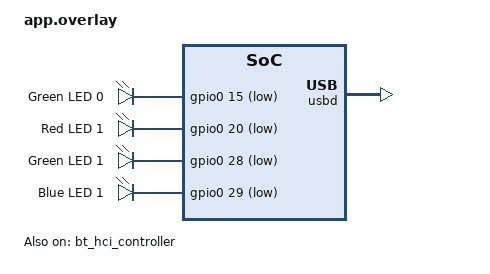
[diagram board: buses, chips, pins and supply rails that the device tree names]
/ {
	chosen {
		zephyr,bt-hci = &bt_hci_controller;
	};

	/* Configure DTS nodes used for USB next HID support. */
	hid_dev_0: hid_dev_0 {
		compatible = "zephyr,hid-device";
		interface-name = "HID0";
		protocol-code = "none";
		in-polling-period-us = <1000>;
		in-report-size = <64>;
	};
	hid_dev_1: hid_dev_1 {
		compatible = "zephyr,hid-device";
		interface-name = "HID1";
		protocol-code = "none";
		in-polling-period-us = <1000>;
		in-report-size = <64>;
	};

	gpioled1 {
		compatible = "gpio-leds";
		status = "okay";
		label = "LED System State";

		led0_g: led_0 {
			gpios = <&gpio0 15 GPIO_ACTIVE_LOW>;
			label = "Green LED 0";
		};
	};
	gpioled2 {
		compatible = "gpio-leds";
		status = "okay";
		label = "LED BLE State";

		led1_r: led_1 {
			gpios = <&gpio0 20 GPIO_ACTIVE_LOW>;
			label = "Red LED 1";
		};
		led1_g: led_2 {
			gpios = <&gpio0 28 GPIO_ACTIVE_LOW>;
			label = "Green LED 1";
		};
		led1_b: led_3 {
			gpios = <&gpio0 29 GPIO_ACTIVE_LOW>;
			label = "Blue LED 1";
		};

	};
	leds {
		status = "disabled";
	};
};


&usbd {
	compatible = "nordic,nrf-usbd";
	status = "okay";
	num-bidir-endpoints = <0>;
	num-in-endpoints = <4>;
	num-out-endpoints = <2>;
	num-isoin-endpoints = <0>;
	num-isoout-endpoints = <0>;
};

&bt_hci_controller {
	status = "okay";
};

&bt_hci_sdc {
	status = "disabled";
};
